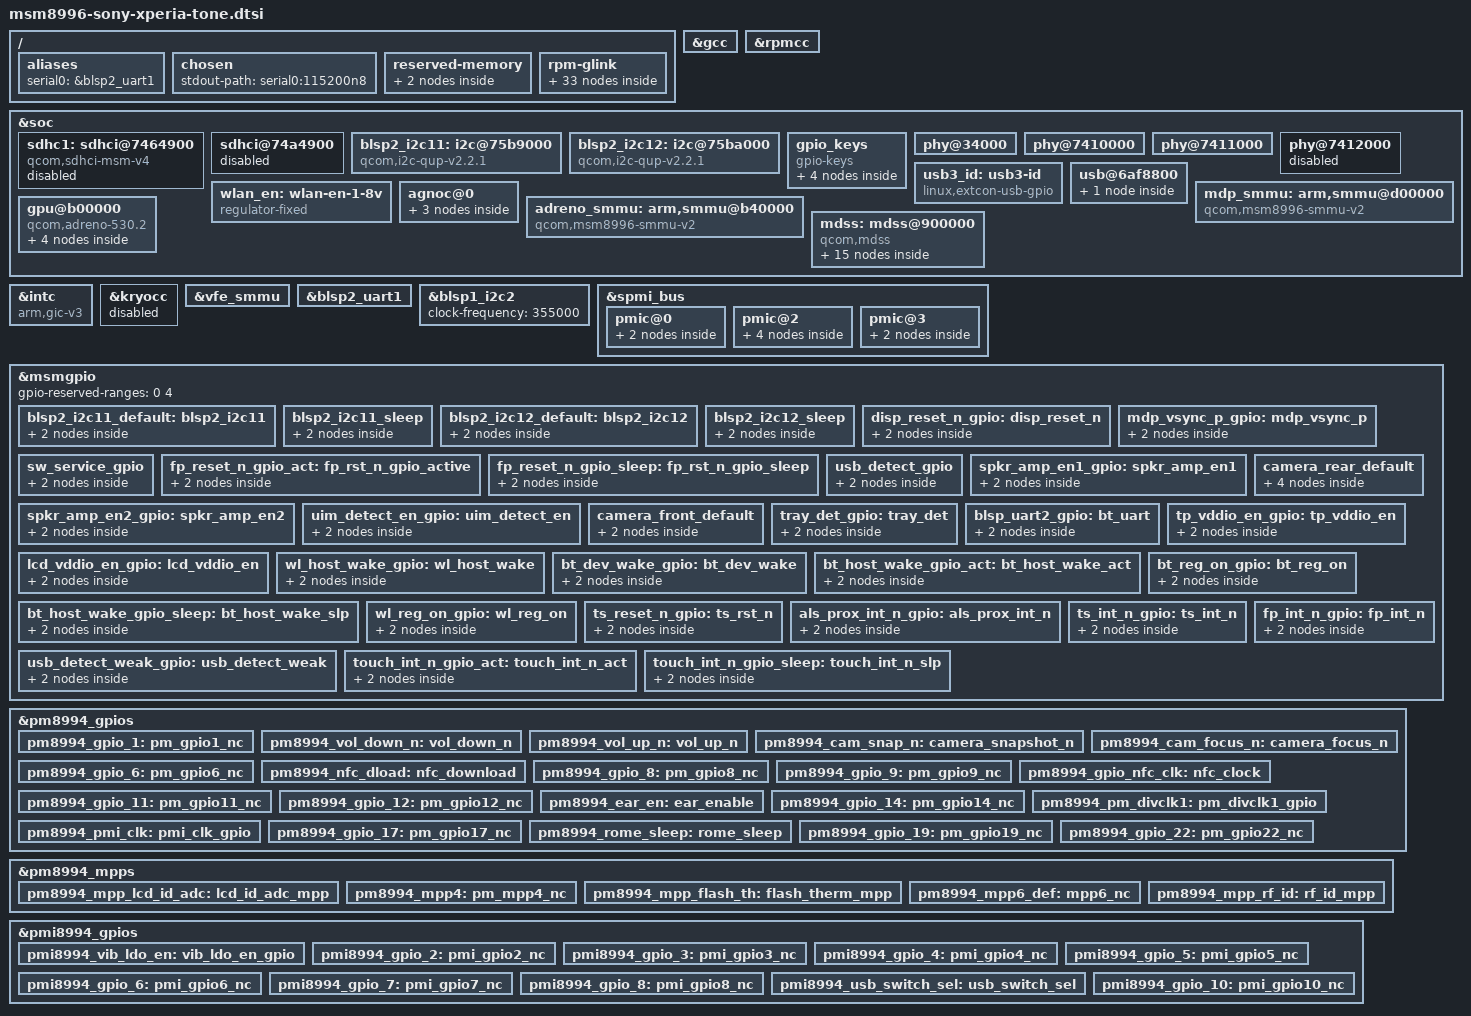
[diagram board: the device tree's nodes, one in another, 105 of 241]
// SPDX-License-Identifier: GPL-2.0
/* Copyright (C) 2016 Sony Mobile Communications Inc.
 * Copyright (c) 2019 AngeloGioacchino Del Regno <kholk11@gmail.com>
 */

#include "msm8996.dtsi"
#include "pm8994.dtsi"
#include "pmi8994.dtsi"
#include <dt-bindings/input/input.h>
#include <dt-bindings/input/gpio-keys.h>
#include <dt-bindings/gpio/gpio.h>
#include <dt-bindings/pinctrl/qcom,pmic-gpio.h>
#include <dt-bindings/pinctrl/qcom,pmic-mpp.h>

/ {
	aliases {
		serial0 = &blsp2_uart1;
	};

	chosen {
		stdout-path = "serial0:115200n8";
	};

	reserved-memory {
		ramoops {
			compatible = "removed-dma-pool", "ramoops";
			no-map;
			reg = <0 0x57f00000 0 0x00100000>;
			record-size = <0x20000>;
			console-size = <0x40000>;
			ftrace-size = <0x20000>;
			pmsg-size = <0x20000>;
			ecc-size = <16>;
			status = "ok";
		};

		zap_shader_region: gpu@8f200000 {
			compatible = "shared-dma-pool";
			reg = <0x0 0x91700000 0x0 0xa00000>;
			no-map;
			status = "ok";
		};
	};

	rpm-glink {
		rpm_requests {
			pm8994-regulators {
				vdd_l1-supply = <&pm8994_s3>;
				vdd_l2_l26_l28-supply = <&pm8994_s3>;
				vdd_l3_l11-supply = <&pm8994_s3>;
				vdd_l4_l27_l31-supply = <&pm8994_s3>;
				vdd_l5_l7-supply = <&pm8994_s5>;
				vdd_l14_l15-supply = <&pm8994_s5>;
				vdd_l20_l21-supply = <&pm8994_s5>;
				vdd_l25-supply = <&pm8994_s3>;

				s3 {
					regulator-min-microvolt = <1300000>;
					regulator-max-microvolt = <1300000>;
				};

				s4 {
					regulator-min-microvolt = <1800000>;
					regulator-max-microvolt = <1800000>;
					regulator-always-on;
				};
				s5 {
					regulator-min-microvolt = <2150000>;
					regulator-max-microvolt = <2150000>;
				};
				s7 {
					regulator-min-microvolt = <800000>;
					regulator-max-microvolt = <800000>;
				};

				l1 {
					regulator-min-microvolt = <1000000>;
					regulator-max-microvolt = <1000000>;
				};
				l2 {
					regulator-min-microvolt = <1250000>;
					regulator-max-microvolt = <1250000>;
				};
				l3 {
					regulator-min-microvolt = <1100000>;
					regulator-max-microvolt = <1100000>;
				};
				l4 {
					regulator-min-microvolt = <1225000>;
					regulator-max-microvolt = <1225000>;
				};
				l6 {};
				l7 {};
				l8 {
					regulator-min-microvolt = <1800000>;
					regulator-max-microvolt = <1800000>;
				};
				l9 {
					regulator-min-microvolt = <1800000>;
					regulator-max-microvolt = <1800000>;
				};
				l10 {
					regulator-min-microvolt = <1800000>;
					regulator-max-microvolt = <1800000>;
				};
				l11 {};
				l12 {
					regulator-min-microvolt = <1800000>;
					regulator-max-microvolt = <1800000>;
				};
				l13 {
					regulator-min-microvolt = <1800000>;
					regulator-max-microvolt = <2950000>;
				};
				l14 {};
				l15 {
					regulator-min-microvolt = <1800000>;
					regulator-max-microvolt = <1800000>;
				};
				l16 {
					regulator-min-microvolt = <2700000>;
					regulator-max-microvolt = <2700000>;
				};
				l17 {
					regulator-min-microvolt = <2200000>;
					regulator-max-microvolt = <2500000>;
				};
				l18 {
					regulator-min-microvolt = <1800000>;
					regulator-max-microvolt = <1800000>;
				};
				l20 {
					regulator-min-microvolt = <2950000>;
					regulator-max-microvolt = <2950000>;
					regulator-allow-set-load;
				};
				l21 {
					regulator-min-microvolt = <2950000>;
					regulator-max-microvolt = <2950000>;
				};
				l22 {
					regulator-min-microvolt = <3000000>;
					regulator-max-microvolt = <3000000>;
				};
				l23 {
					regulator-min-microvolt = <2700000>;
					regulator-max-microvolt = <2700000>;
				};
				l24 {
					regulator-min-microvolt = <3075000>;
					regulator-max-microvolt = <3075000>;
					regulator-allow-set-load;
				};
				l25 {
					regulator-min-microvolt = <1200000>;
					regulator-max-microvolt = <1200000>;
					regulator-allow-set-load;
				};
				l27 {
					regulator-min-microvolt = <1000000>;
					regulator-max-microvolt = <1200000>;
				};
				l28 { /* This should be 1.0V for USB, 0.925 for DSI :\ */
					regulator-min-microvolt = <925000>;
					regulator-max-microvolt = <925000>;
					regulator-allow-set-load;
				};
				l29 {
					regulator-min-microvolt = <2700000>;
					regulator-max-microvolt = <2700000>;
				};
				l32 {
					regulator-min-microvolt = <1800000>;
					regulator-max-microvolt = <1800000>;
				};
			};
		};
	};
};

&gcc {
	status = "ok";
};

&rpmcc {
	status = "ok";
};

&soc {
	sdhc1: sdhci@7464900 {
		compatible = "qcom,sdhci-msm-v4";
		reg = <0x7464900 0x500>, <0x7464000 0x800>;
		reg-names = "hc_mem", "core_mem";

		interrupts = <GIC_SPI 141 IRQ_TYPE_LEVEL_HIGH>,
			     <GIC_SPI 134 IRQ_TYPE_LEVEL_HIGH>;
		interrupt-names = "hc_irq", "pwr_irq";

		clock-names = "iface", "core", "xo";
		clocks = <&gcc GCC_SDCC1_AHB_CLK>,
			 <&gcc GCC_SDCC1_APPS_CLK>,
			 <&xo_board>;

		mmc-hs400-1_8v;
		bus-width = <8>;
		non-removable;
		status = "disabled";
	};

	sdhci@74a4900 {
		pinctrl-names = "default", "sleep";
		pinctrl-0 = <&sdc2_clk_on &sdc2_cmd_on &sdc2_data_on
				&tray_det_gpio>;
		pinctrl-1 = <&sdc2_clk_off &sdc2_cmd_off &sdc2_data_off
				&tray_det_gpio>;
		cd-gpios = <&msmgpio 40 GPIO_ACTIVE_LOW>;
		vmmc-supply = <&pm8994_l21>;
		vqmmc-supply = <&pm8994_l13>;
		status = "disabled";
	};

	blsp2_i2c11: i2c@75b9000 {
		compatible = "qcom,i2c-qup-v2.2.1";
		reg = <0x75b9000 0x1000>;
		interrupts = <GIC_SPI 102 IRQ_TYPE_LEVEL_HIGH>;
		clocks = <&gcc GCC_BLSP2_AHB_CLK>,
			<&gcc GCC_BLSP2_QUP5_I2C_APPS_CLK>;
		clock-names = "iface", "core";
		pinctrl-names = "default", "sleep";
		pinctrl-0 = <&blsp2_i2c11_default>;
		pinctrl-1 = <&blsp2_i2c11_sleep>;
		#address-cells = <1>;
		#size-cells = <0>;

		clock-frequency = <355000>;
		status = "ok";
	};

	blsp2_i2c12: i2c@75ba000 {
		compatible = "qcom,i2c-qup-v2.2.1";
		reg = <0x75ba000 0x1000>;
		interrupts = <GIC_SPI 102 IRQ_TYPE_LEVEL_HIGH>;
		clocks = <&gcc GCC_BLSP2_AHB_CLK>,
			<&gcc GCC_BLSP2_QUP6_I2C_APPS_CLK>;
		clock-names = "iface", "core";
		pinctrl-names = "default", "sleep";
		pinctrl-0 = <&blsp2_i2c12_default>;
		pinctrl-1 = <&blsp2_i2c12_sleep>;
		#address-cells = <1>;
		#size-cells = <0>;

		clock-frequency = <355000>;
		status = "ok";
	};

	gpio_keys {
		compatible = "gpio-keys";
		input-name = "gpio-keys";
		#address-cells = <1>;
		#size-cells = <0>;
		autorepeat;

		button@0 {
			label = "Volume Down";
			gpios = <&pm8994_gpios 2 GPIO_ACTIVE_LOW>;
			linux,input-type = <1>;
			linux,code = <KEY_VOLUMEDOWN>;
			wakeup-source;
			debounce-interval = <15>;
		};

		button@1 {
			label = "Volume Up";
			gpios = <&pm8994_gpios 3 GPIO_ACTIVE_LOW>;
			linux,input-type = <1>;
			linux,code = <KEY_VOLUMEUP>;
			wakeup-source;
			debounce-interval = <15>;
		};

		button@2 {
			label = "Camera Snapshot";
			gpios = <&pm8994_gpios 4 GPIO_ACTIVE_LOW>;
			linux,input-type = <1>;
			linux,code = <KEY_CAMERA>;
			wakeup-source;
			wakeup-event-action = <EV_ACT_ASSERTED>;
			debounce-interval = <15>;
		};

		button@3 {
			label = "Camera Focus";
			gpios = <&pm8994_gpios 5 GPIO_ACTIVE_LOW>;
			linux,input-type = <1>;
			linux,code = <KEY_CAMERA_FOCUS>;
			wakeup-source;
			debounce-interval = <15>;
		};
	};

	phy@34000 {
		status = "okay";
	};

	phy@7410000 {
		status = "okay";
	};

	phy@7411000 {
		status = "okay";
	};

	phy@7412000 {
		status = "disabled";
	};

	usb3_id: usb3-id {
		compatible = "linux,extcon-usb-gpio";
		id-gpio = <&msmgpio 24 GPIO_ACTIVE_LOW>;
		pinctrl-names = "default";
		pinctrl-0 = <&usb_detect_gpio>;
	};

	usb@6af8800 {
		status = "okay";
		extcon = <&usb3_id>;

		clock-names = "cfg_noc", "core", "iface", "mock_utmi",
				"sleep", "ahb2phy";
		resets = <&gcc GCC_USB_30_BCR>,
			 <&gcc GCC_USB_PHY_CFG_AHB2PHY_BCR>;
		reset-names = "core_reset", "ahb2phy_reset";

		interrupts = <GIC_SPI 347 IRQ_TYPE_LEVEL_HIGH>,
			     <GIC_SPI 243 IRQ_TYPE_LEVEL_HIGH>;
		interrupt-names = "hs_phy_irq", "ss_phy_irq";

		dwc3@6a00000 {
			extcon = <&usb3_id>;
			dr_mode = "otg";
			maximum-speed = "high-speed";
			snps,has-lpm-erratum;
			snps,is-utmi-l1-suspend;
			snps,hird-threshold = /bits/ 8 <0x0>;
			phys = <&hsusb_phy1>; //, <&ssusb_phy_0>;
			phy-names = "usb2-phy"; //, "usb3-phy";
		};
	};

	wlan_en: wlan-en-1-8v {
		pinctrl-names = "default";
		pinctrl-0 = <&wl_reg_on_gpio>;
		compatible = "regulator-fixed";
		regulator-name = "wlan-en-regulator";
		regulator-min-microvolt = <1800000>;
		regulator-max-microvolt = <1800000>;

		gpio = <&msmgpio 84 GPIO_ACTIVE_HIGH>;

		/* WLAN card specific delay */
		startup-delay-us = <70000>;
		enable-active-high;
	};

	agnoc@0 {
		pcie@600000 {
			status = "okay";
			perst-gpio = <&msmgpio 35 GPIO_ACTIVE_LOW>;
			wake-gpio = <&msmgpio 37 GPIO_ACTIVE_LOW>;
			vddpe-3v3-supply = <&wlan_en>;
		};

		pcie@608000 {
			status = "disabled";
			perst-gpio = <&msmgpio 130 GPIO_ACTIVE_LOW>;
		};

		pcie@610000 {
			status = "disabled";
			perst-gpio = <&msmgpio 114 GPIO_ACTIVE_LOW>;
			wake-gpio = <&msmgpio 116 GPIO_ACTIVE_LOW>;
		};
	};

	adreno_smmu: arm,smmu@b40000 {
		compatible = "qcom,msm8996-smmu-v2", "qcom,smmu-v2";
		reg = <0xb40000 0x10000>;

		#global-interrupts = <1>;
		interrupts = <GIC_SPI 334 IRQ_TYPE_LEVEL_HIGH>,
			     <GIC_SPI 329 IRQ_TYPE_LEVEL_HIGH>,
			     <GIC_SPI 330 IRQ_TYPE_LEVEL_HIGH>;
		#iommu-cells = <1>;

/*
		clocks = <&mmcc GPU_AHB_CLK>,
			<&gcc GCC_MMSS_BIMC_GFX_CLK>;
		clock-names = "bus", "iface";
*/
		clocks = <&mmcc MMSS_MMAGIC_AHB_CLK>,
			<&mmcc MMSS_MMAGIC_CFG_AHB_CLK>,
			<&mmcc GPU_AHB_CLK>,
			<&gcc GCC_MMSS_BIMC_GFX_CLK>,
			<&gcc GCC_BIMC_GFX_CLK>;
		clock-names = "mmagic_ahb_clk", "mmagic_cfg_ahb_clk", "gpu_ahb_clk",
			"gcc_mmss_bimc_gfx_clk", "gcc_bimc_gfx_clk";

		power-domains = <&mmcc GPU_GDSC>;

		status = "ok";
	};

	mdp_smmu: arm,smmu@d00000 {
		compatible = "qcom,msm8996-smmu-v2", "qcom,smmu-v2";
		reg = <0xd00000 0x10000>;

		#global-interrupts = <1>;
		interrupts = <GIC_SPI 73 IRQ_TYPE_LEVEL_HIGH>,
			     <GIC_SPI 320 IRQ_TYPE_LEVEL_HIGH>,
			     <GIC_SPI 321 IRQ_TYPE_LEVEL_HIGH>;
		#iommu-cells = <1>;

		power-domains = <&mmcc MDSS_GDSC>;
/*
		clocks = <&mmcc SMMU_MDP_AHB_CLK>,
			 <&mmcc SMMU_MDP_AXI_CLK>;
		clock-names = "iface", "bus";
*/
		clocks = <&mmcc MMSS_MMAGIC_AHB_CLK>,
			<&mmcc MMSS_MMAGIC_CFG_AHB_CLK>,
			<&mmcc SMMU_MDP_AHB_CLK>,
			<&mmcc SMMU_MDP_AXI_CLK>,
			<&mmcc MMAGIC_MDSS_AXI_CLK>;
		clock-names = "mmagic_ahb_clk", "mmagic_cfg_ahb_clk",
			"mdp_ahb_clk", "mdp_axi_clk",
			"mmagic_mdss_axi_clk";

		status = "ok";
	};

	gpu@b00000 {
		compatible = "qcom,adreno-530.2", "qcom,adreno";
		#stream-id-cells = <16>;

		reg = <0xb00000 0x3f000>;
		reg-names = "kgsl_3d0_reg_memory";

		interrupts = <GIC_SPI 300 IRQ_TYPE_LEVEL_HIGH>;
		interrupt-names = "kgsl_3d0_irq";

		clocks = <&mmcc GPU_GX_GFX3D_CLK>,
			<&mmcc GPU_AHB_CLK>,
			<&mmcc GPU_GX_RBBMTIMER_CLK>,
			<&gcc GCC_BIMC_GFX_CLK>,
			<&gcc GCC_MMSS_BIMC_GFX_CLK>;

		clock-names = "core",
			"iface",
			"rbbmtimer",
			"mem",
			"mem_iface";

		power-domains = <&mmcc GPU_GDSC>;
		vdd-supply = <&pmi8994_s2>;
		iommus = <&adreno_smmu 0>;

		qcom,gpu-quirk-two-pass-use-wfi;
		qcom,gpu-quirk-fault-detect-mask;

		/* This is a safe speed for bring up in all bin levels.
		 * This isn't the fastest the chip can go, but we can
		 * get there eventually */
		qcom,gpu-pwrlevels {
			compatible = "qcom,gpu-pwrlevels";
			qcom,gpu-pwrlevel@0 {
				qcom,gpu-freq = <510000000>;
			};
			qcom,gpu-pwrlevel@1 {
				qcom,gpu-freq = <27000000>;
			};
		};

		zap-shader {
			memory-region = <&zap_shader_region>;
		};
	};

	mdss: mdss@900000 {
		compatible = "qcom,mdss";

		reg = <0x900000 0x1000>,
		      <0x9b0000 0x1040>,
		      <0x9b8000 0x1040>;
		reg-names = "mdss_phys",
			    "vbif_phys",
			    "vbif_nrt_phys";

		power-domains = <&mmcc MDSS_GDSC>;
		interrupts = <GIC_SPI 83 IRQ_TYPE_LEVEL_HIGH>;

		interrupt-controller;
		#interrupt-cells = <1>;

		clocks = <&mmcc MDSS_AHB_CLK>,
			 <&mmcc MDSS_AXI_CLK>,
			 <&mmcc MDSS_VSYNC_CLK>;
		clock-names = "iface", "bus", "vsync";

		#address-cells = <1>;
		#size-cells = <1>;
		ranges;

		mdp: mdp@901000 {
			compatible = "qcom,mdp5";
			reg = <0x901000 0x90000>;
			reg-names = "mdp_phys";

			interrupt-parent = <&mdss>;
			interrupts = <0 IRQ_TYPE_LEVEL_HIGH>;

			clocks = <&mmcc MDSS_AHB_CLK>,
				 <&mmcc MDSS_AXI_CLK>,
				 <&mmcc MDSS_MDP_CLK>,
				 <&mmcc SMMU_MDP_AXI_CLK>,
				 <&mmcc MDSS_VSYNC_CLK>;
			clock-names = "iface",
				      "bus",
				      "core",
				      "iommu",
				      "vsync";

			iommus = <&mdp_smmu 0>;

			ports {
				#address-cells = <1>;
				#size-cells = <0>;

				port@0 {
					reg = <0>;
					mdp5_intf1_out: endpoint {
						remote-endpoint = <&dsi0_in>;
					};
				};
			};
		};

		dsi0: dsi@994000 {
			compatible = "qcom,mdss-dsi-ctrl";
			reg = <0x994000 0x400>;
			reg-names = "dsi_ctrl";
			qcom,dsi-host-index = <0>;

			interrupt-parent = <&mdss>;
			interrupts = <4 0>;

			#address-cells = <1>;
			#size-cells = <0>;

			clocks = <&mmcc MDSS_MDP_CLK>,
				 <&mmcc MDSS_AHB_CLK>,
				 <&mmcc MDSS_AXI_CLK>,
				 <&mmcc MMSS_MISC_AHB_CLK>,
				 <&mmcc MDSS_BYTE0_CLK>,
				 <&mmcc MDSS_PCLK0_CLK>,
				 <&mmcc MDSS_ESC0_CLK>;
			clock-names = "mdp_core",
				      "iface",
				      "bus",
				      "core_mmss",
				      "byte",
				      "pixel",
				      "core";

			assigned-clocks =
					<&mmcc BYTE0_CLK_SRC>,
					<&mmcc PCLK0_CLK_SRC>;
			assigned-clock-parents =
					<&dsi_phy0 0>,
					<&dsi_phy0 1>;

			vdda-supply = <&pm8994_l2>;
			vcca-supply = <&pm8994_l28>;

			phys = <&dsi_phy0>;
			phy-names = "dsi-phy";

			ports {
				#address-cells = <1>;
				#size-cells = <0>;

				port@0 {
					reg = <0>;
					dsi0_in: endpoint {
						remote-endpoint = <&mdp5_intf1_out>;
					};
				};

				port@1 {
					reg = <1>;
					dsi0_out: endpoint {
						remote-endpoint = <&panel_in>;
						data-lanes = <0 1 2 3>;
					};
				};
			};

			lgd_panel0: lgd-panel@0 {
				compatible = "lgd,syn-incell-fhd-ips-lcd";
				reg = <0>;
				status = "okay";
				disp-te-gpio = <&msmgpio 10 0>;

				vddio-supply = <&pm8994_s4>;
				avdd-supply = <&pm8994_l22>;

				pvddio-gpio = <&msmgpio 51 GPIO_ACTIVE_HIGH>;
				preset-gpio = <&msmgpio 8 GPIO_ACTIVE_HIGH>;
				tvddio-gpio = <&msmgpio 50 GPIO_ACTIVE_HIGH>;
				treset-gpio = <&msmgpio 89 GPIO_ACTIVE_HIGH>;

				pinctrl-names = "default";
				pinctrl-0 =
					<&mdp_vsync_p_gpio &disp_reset_n_gpio
					&tp_vddio_en_gpio &lcd_vddio_en_gpio
					&ts_reset_n_gpio>;

				ports {
					#address-cells = <1>;
					#size-cells = <0>;
					port@0 {
						reg = <0>;
						panel_in: endpoint {
							remote-endpoint = <&dsi0_out>;
						};
					};
				};
			};
		};

		dsi_phy0: dsi-phy@994800 {
			compatible = "qcom,dsi-phy-14nm";
			reg = <0x994800 0x188>,
			      <0x994400 0x100>,
			      <0x994500 0x300>;
			reg-names = "dsi_pll",
				    "dsi_phy",
				    "dsi_phy_lane";

			#clock-cells = <1>;
			#phy-cells = <0>;

			power-domains = <&mmcc MDSS_GDSC>;
			vcca-supply = <&pm8994_l28>;

			clocks = <&mmcc MDSS_AHB_CLK>;
			clock-names = "iface";
		};
	};

};

&intc {
	compatible = "arm,gic-v3", "qcom,msm8996-gic-v3";
};

&kryocc {
	status = "disabled";
};

&vfe_smmu {
	status = "ok";
};

&blsp2_uart1 {
	status = "ok";
	pinctrl-names = "default", "sleep";
	pinctrl-0 = <&blsp2_uart1_2pins_default>;
	pinctrl-1 = <&blsp2_uart1_2pins_sleep>;
};

&blsp1_i2c2 {
	clock-frequency = <355000>;
	status = "ok";
};

&spmi_bus {
	pmic@0 {
		pon@800 {
			resin {
				compatible = "qcom,pm8941-resin";
				interrupts = <0x0 0x8 1 IRQ_TYPE_EDGE_BOTH>;
				debounce = <15625>;
				bias-pull-up;
				linux,code = <KEY_VOLUMEUP>;
			};
		};
	};

	pmic@2 {
		pmi8994_mpps: pmi-mpps {
			compatible = "qcom,pmi8994-mpp"; /* TODO: Not supported! */
			reg = <0xa000 0x400>;

			interrupts = <0x2 0xa0 0 IRQ_TYPE_NONE>,
				<0x2 0xa1 0 IRQ_TYPE_NONE>,
				<0x2 0xa2 0 IRQ_TYPE_NONE>,
				<0x2 0xa3 0 IRQ_TYPE_NONE>;
			interrupt-names = "pmi8994_mpp1", "pmi8994_mpp2",
					  "pmi8994_mpp3", "pmi8994_mpp4";

			gpio-controller;
			#gpio-cells = <2>;
		};
	};

	pmic@3 {
		regulators {
			compatible = "qcom,pmi8994-regulators";
			#address-cells = <1>;
			#size-cells = <1>;

			/* GPU GX GDSC Supply */
			pmi8994_s2: s2@1700 {
				reg = <0x1700 0x100>;
				status = "ok";
				regulator-min-microvolt = <400000>;
				regulator-max-microvolt = <1015000>;
				regulator-always-on;
			};
		};
	};
};

/* Pins */
&msmgpio {
	gpio-reserved-ranges = <0 4>;

	blsp2_i2c11_default: blsp2_i2c11 {
		pinmux {
			function = "blsp_i2c11";
			pins = "gpio60", "gpio61";
		};
		pinconf {
			pins = "gpio60", "gpio61";
			drive-strength = <16>;
			bias-disable;
		};
	};

	blsp2_i2c11_sleep: blsp2_i2c11_sleep {
		pinmux {
			function = "gpio";
			pins = "gpio60", "gpio61";
		};
		pinconf {
			pins = "gpio60", "gpio61";
			drive-strength = <2>;
			bias-disable;
		};
	};

	blsp2_i2c12_default: blsp2_i2c12 {
		pinmux {
			function = "blsp_i2c12";
			pins = "gpio87", "gpio88";
		};
		pinconf {
			pins = "gpio87", "gpio88";
			drive-strength = <16>;
			bias-disable;
		};
	};

	blsp2_i2c12_sleep: blsp2_i2c12_sleep {
		pinmux {
			function = "gpio";
			pins = "gpio87", "gpio88";
		};
		pinconf {
			pins = "gpio87", "gpio88";
			drive-strength = <2>;
			bias-disable;
		};
	};

	disp_reset_n_gpio: disp_reset_n {
		pinmux {
			pins = "gpio8";
			function = "gpio";
		};

		pinconf {
			pins = "gpio8";
			drive-strength = <2>;
			bias-disable;
		};
	};

	mdp_vsync_p_gpio: mdp_vsync_p {
		pinmux {
			pins = "gpio10";
			function = "mdp_vsync";
		};

		pinconf {
			pins = "gpio10";
			drive-strength = <2>;
			bias-disable;
		};
	};

	sw_service_gpio: sw_service_gpio {
		pinmux {
			pins = "gpio16";
			function = "gpio";
		};

		pinconf {
			pins = "gpio16";
			drive-strength = <2>;
			bias-pull-up;
		};
	};

	fp_reset_n_gpio_act: fp_rst_n_gpio_active {
		pinmux {
			pins = "gpio21";
			function = "gpio";
		};

		pinconf {
			pins = "gpio21";
			drive-strength = <2>;
			bias-disable;
			output-high;
		};
	};

	fp_reset_n_gpio_sleep: fp_rst_n_gpio_sleep {
		pinmux {
			pins = "gpio21";
			function = "gpio";
		};

		pinconf {
			pins = "gpio21";
			drive-strength = <2>;
			bias-disable;
			output-low;
		};
	};

	usb_detect_gpio: usb_detect_gpio {
		pinmux {
			pins = "gpio24";
			function = "gpio";
		};

		pinconf {
			pins = "gpio24";
			drive-strength = <2>;
			bias-disable;
			output-low;
		};
	};

	spkr_amp_en1_gpio: spkr_amp_en1 {
		pinmux {
			pins = "gpio27";
			function = "gpio";
		};

		pinconf {
			pins = "gpio27";
			drive-strength = <2>;
			bias-disable;
			output-low;
		};
	};

	spkr_amp_en2_gpio: spkr_amp_en2 {
		pinmux {
			pins = "gpio28";
			function = "gpio";
		};

		pinconf {
			pins = "gpio28";
			drive-strength = <2>;
			bias-disable;
			output-low;
		};
	};

	uim_detect_en_gpio: uim_detect_en {
		pinmux {
			pins = "gpio29";
			function = "gpio";
		};

		pinconf {
			pins = "gpio29";
			drive-strength = <2>;
			bias-disable;
			output-low;
		};
	};


	camera_rear_default {
		config_pwdn {
			drive-strength = <2>;
			output-low;
		};

		mux_rst {
			pins = "gpio30";
		};

		config_rst {
			pins = "gpio30";
			drive-strength = <2>;
			output-low;
		};

		config_mclk0 {
			drive-strength = <2>;
			output-low;
		};
	};

	camera_front_default {
		config_rst {
			drive-strength = <2>;
			output-low;
		};

		config_mclk2 {
			drive-strength = <2>;
			output-low;
		};
	};

	tray_det_gpio: tray_det {
		pinmux {
			pins = "gpio40";
			function = "gpio";
		};

		pinconf {
			pins = "gpio40";
			drive-strength = <2>;
			bias-disable;
		};
	};

	blsp_uart2_gpio: bt_uart {
		pinmux {
			function = "blsp_uart2";
			pins = "gpio41", "gpio42", "gpio43", "gpio44";
		};
		pinconf {
			pins = "gpio41", "gpio42", "gpio43", "gpio44";
			drive-strength = <2>;
			bias-disable;
		};
	};

	tp_vddio_en_gpio: tp_vddio_en {
		pinmux {
			pins = "gpio50";
			function = "gpio";
		};

		pinconf {
			pins = "gpio50";
			drive-strength = <2>;
			bias-disable;
			output-low;
		};
	};

	lcd_vddio_en_gpio: lcd_vddio_en {
		pinmux {
			pins = "gpio51";
			function = "gpio";
		};

		pinconf {
			pins = "gpio51";
			drive-strength = <2>;
			bias-disable;
			output-low;
		};
	};

	wl_host_wake_gpio: wl_host_wake {
		pinmux {
			pins = "gpio79";
			function = "gpio";
		};

		pinconf {
			pins = "gpio79";
			drive-strength = <2>;
			bias-pull-down;
		};
	};

	bt_dev_wake_gpio: bt_dev_wake {
		pinmux {
			pins = "gpio81";
			function = "gpio";
		};

		pinconf {
			pins = "gpio81";
			drive-strength = <2>;
			bias-disable;
			output-low;
		};
	};

	bt_host_wake_gpio_act: bt_host_wake_act {
		pinmux {
			pins = "gpio82";
			function = "gpio";
		};

		pinconf {
			pins = "gpio82";
			drive-strength = <2>;
			bias-disable;
		};
	};

	bt_host_wake_gpio_sleep: bt_host_wake_slp {
		pinmux {
			pins = "gpio82";
			function = "gpio";
		};

		pinconf {
			pins = "gpio82";
			drive-strength = <2>;
			bias-pull-down;
		};
	};

	bt_reg_on_gpio: bt_reg_on {
		pinmux {
			pins = "gpio83";
			function = "gpio";
		};

		pinconf {
			pins = "gpio83";
			drive-strength = <2>;
			bias-disable;
			output-low;
		};
	};

	wl_reg_on_gpio: wl_reg_on {
		pinmux {
			pins = "gpio84";
			function = "gpio";
		};

		pinconf {
			pins = "gpio84";
			drive-strength = <2>;
			bias-disable;
			output-low;
		};
	};

	ts_reset_n_gpio: ts_rst_n {
		pinmux {
			pins = "gpio89";
			function = "gpio";
		};

		pinconf {
			pins = "gpio89";
			drive-strength = <2>;
		};
	};

	als_prox_int_n_gpio: als_prox_int_n {
		pinmux {
			pins = "gpio120";
			function = "gpio";
		};

		pinconf {
			pins = "gpio120";
			drive-strength = <2>;
			bias-disable;
		};
	};

	ts_int_n_gpio: ts_int_n {
		pinmux {
			pins = "gpio125";
			function = "gpio";
		};

		pinconf {
			pins = "gpio125";
			drive-strength = <2>;
		};
	};

	usb_detect_weak_gpio: usb_detect_weak {
		pinmux {
			pins = "gpio130";
			function = "gpio";
		};

		pinconf {
			pins = "gpio130";
			drive-strength = <2>;
			bias-disable;
			output-low;
		};
	};

	fp_int_n_gpio: fp_int_n {
		pinmux {
			pins = "gpio132";
			function = "gpio";
		};

		pinconf {
			pins = "gpio132";
			drive-strength = <2>;
			bias-pull-down;
		};
	};

	touch_int_n_gpio_act: touch_int_n_act {
		pinmux {
			pins = "gpio125";
			function = "touch_int_n";
		};
		pinconf {
			pins = "gpio125";
			drive-strength = <2>;
			bias-pull-up;
		};
	};

	touch_int_n_gpio_sleep: touch_int_n_slp {
		pinmux {
			pins = "gpio125";
			function = "touch_int_n";
		};
		pinconf {
			pins = "gpio125";
			drive-strength = <2>;
			bias-pull-down;
		};
	};
};

/* PMIC Pins */
&pm8994_gpios {
	pinctrl-names = "default";
	pinctrl-0 = <&pm8994_gpio_1 &pm8994_vol_down_n &pm8994_vol_up_n
		     &pm8994_cam_snap_n &pm8994_cam_focus_n &pm8994_gpio_6
		     &pm8994_nfc_dload &pm8994_gpio_8 &pm8994_gpio_9
		     &pm8994_gpio_nfc_clk &pm8994_gpio_11 &pm8994_gpio_12
		     &pm8994_ear_en &pm8994_gpio_14 &pm8994_pm_divclk1
		     &pm8994_pmi_clk &pm8994_gpio_17 &pm8994_rome_sleep
		     &pm8994_gpio_19 &pm8994_gpio_22>;

	gpio-line-names =
		"NC",
		"VOL_DOWN_N",
		"VOL_UP_N",
		"SNAPSHOT_N",
		"FOCUS_N",
		"NC",
		"NFC_VEN",
		"NC",
		"NC",
		"NC",
		"NC",
		"NC",
		"EAR_EN",
		"NC",
		"PM_DIVCLK1",
		"PMI_CLK",
		"NC",
		"WL_SLEEP_CLK",
		"NC",
		"PMIC_SPON",
		"UIM_BATT_ALARM",
		"PMK_SLEEP_CLK";

	pm8994_gpio_1: pm_gpio1_nc {
		pins = "gpio1";
		function = PMIC_GPIO_FUNC_NORMAL;
		drive-push-pull;
		bias-high-impedance;
	};

	pm8994_vol_down_n: vol_down_n {
		pins = "gpio2";
		function = PMIC_GPIO_FUNC_NORMAL;
		drive-push-pull;
		input-enable;
		bias-pull-up;
		qcom,drive-strength = <PMIC_GPIO_STRENGTH_NO>;
		power-source = <PM8994_GPIO_S4>;
	};

	pm8994_vol_up_n: vol_up_n {
		pins = "gpio3";
		function = PMIC_GPIO_FUNC_NORMAL;
		drive-push-pull;
		input-enable;
		bias-pull-up;
		power-source = <PM8994_GPIO_S4>;
	};

	pm8994_cam_snap_n: camera_snapshot_n {
		pins = "gpio4";
		function = PMIC_GPIO_FUNC_NORMAL;
		drive-push-pull;
		input-enable;
		bias-pull-up;
		qcom,drive-strength = <PMIC_GPIO_STRENGTH_NO>;
		power-source = <PM8994_GPIO_S4>;
	};

	pm8994_cam_focus_n: camera_focus_n {
		pins = "gpio5";
		function = PMIC_GPIO_FUNC_NORMAL;
		drive-push-pull;
		input-enable;
		bias-pull-up;
		qcom,drive-strength = <PMIC_GPIO_STRENGTH_NO>;
		power-source = <PM8994_GPIO_S4>;
	};

	pm8994_gpio_6: pm_gpio6_nc {
		pins = "gpio6";
		function = PMIC_GPIO_FUNC_NORMAL;
		drive-push-pull;
		bias-high-impedance;
		power-source = <PM8994_GPIO_VPH>;
	};

	pm8994_nfc_dload: nfc_download {
		pins = "gpio7";
		function = PMIC_GPIO_FUNC_NORMAL;
		output-low;
		drive-push-pull;
		bias-disable;
		qcom,drive-strength = <PMIC_GPIO_STRENGTH_LOW>;
		power-source = <PM8994_GPIO_S4>;
	};

	pm8994_gpio_8: pm_gpio8_nc {
		pins = "gpio8";
		function = PMIC_GPIO_FUNC_NORMAL;
		output-low;
		drive-push-pull;
		bias-high-impedance;
		qcom,drive-strength = <PMIC_GPIO_STRENGTH_NO>;
		power-source = <PM8994_GPIO_VPH>;
	};

	pm8994_gpio_9: pm_gpio9_nc {
		pins = "gpio9";
		function = PMIC_GPIO_FUNC_NORMAL;
		output-high;
		drive-push-pull;
		bias-high-impedance;
		qcom,drive-strength = <PMIC_GPIO_STRENGTH_LOW>;
		power-source = <PM8994_GPIO_VPH>;
	};

	pm8994_gpio_nfc_clk: nfc_clock {
		pins = "gpio10";
		function = PMIC_GPIO_FUNC_NORMAL;
		input-enable;
		drive-push-pull;
		bias-pull-down;
		qcom,drive-strength = <PMIC_GPIO_STRENGTH_NO>;
		power-source = <PM8994_GPIO_S4>;
	};

	pm8994_gpio_11: pm_gpio11_nc {
		pins = "gpio11";
		function = PMIC_GPIO_FUNC_NORMAL;
		drive-push-pull;
		bias-high-impedance;
		power-source = <PM8994_GPIO_VPH>;
	};

	pm8994_gpio_12: pm_gpio12_nc {
		pins = "gpio12";
		function = PMIC_GPIO_FUNC_NORMAL;
		drive-push-pull;
		bias-high-impedance;
		power-source = <PM8994_GPIO_VPH>;
	};

	pm8994_ear_en: ear_enable {
		pins = "gpio13";
		function = PMIC_GPIO_FUNC_NORMAL;
		output-high;
		drive-push-pull;
		bias-disable;
		qcom,drive-strength = <PMIC_GPIO_STRENGTH_LOW>;
		power-source = <PM8994_GPIO_S4>;
	};

	pm8994_gpio_14: pm_gpio14_nc {
		pins = "gpio14";
		function = PMIC_GPIO_FUNC_NORMAL;
		drive-push-pull;
		input-enable;
		bias-high-impedance;
		qcom,drive-strength = <PMIC_GPIO_STRENGTH_LOW>;
		power-source = <PM8994_GPIO_VPH>;
	};

	pm8994_pm_divclk1: pm_divclk1_gpio {
		pins = "gpio15";
		function = "func1";
		output-low;
		drive-push-pull;
		bias-high-impedance;
		qcom,drive-strength = <PMIC_GPIO_STRENGTH_LOW>;
		power-source = <PM8994_GPIO_VPH>;
	};

	pm8994_pmi_clk: pmi_clk_gpio {
		pins = "gpio16";
		function = PMIC_GPIO_FUNC_NORMAL;
		drive-push-pull;
	};

	pm8994_gpio_17: pm_gpio17_nc {
		pins = "gpio17";
		function = PMIC_GPIO_FUNC_NORMAL;
		drive-push-pull;
		bias-high-impedance;
		power-source = <PM8994_GPIO_VPH>;
	};

	pm8994_rome_sleep: rome_sleep {
		pins = "gpio18";
		function = PMIC_GPIO_FUNC_FUNC2;
		output-low;
		drive-push-pull;
		bias-disable;
		qcom,drive-strength = <PMIC_GPIO_STRENGTH_MED>;
		power-source = <PM8994_GPIO_S4>;
	};

	pm8994_gpio_19: pm_gpio19_nc {
		pins = "gpio19";
		function = PMIC_GPIO_FUNC_NORMAL;
		output-low;
		drive-push-pull;
		bias-high-impedance;
		qcom,drive-strength = <PMIC_GPIO_STRENGTH_NO>;
		power-source = <PM8994_GPIO_VPH>;
	};

	pm8994_gpio_22: pm_gpio22_nc {
		pins = "gpio17";
		function = PMIC_GPIO_FUNC_NORMAL;
		drive-push-pull;
		bias-high-impedance;
		power-source = <PM8994_GPIO_VPH>;
	};
};

&pm8994_mpps {
	pinctrl-names = "default";
	pinctrl-0 = <&pm8994_mpp_lcd_id_adc &pm8994_mpp4
			&pm8994_mpp_flash_th &pm8994_mpp6_def
			&pm8994_mpp_rf_id>;

	gpio-line-names =
		"SDC_UIM_VBIAS",
		"LCD_ID_ADC",
		"VREF_DACX",
		"NC",
		"FLASH_THERM",
		"NC",
		"NC",
		"RF_ID";

	pm8994_mpp_lcd_id_adc: lcd_id_adc_mpp {
		pins = "mpp2";
		function = PMIC_MPP_FUNC_ANALOG;
		input-enable;
		qcom,amux-route = <PMIC_MPP_AMUX_ROUTE_CH6>;
	};

	pm8994_mpp4: pm_mpp4_nc {
		pins = "mpp4";
		function = PMIC_MPP_FUNC_DIGITAL;
		bias-high-impedance;
		power-source = <PM8994_GPIO_VPH>;
	};

	pm8994_mpp_flash_th: flash_therm_mpp {
		pins = "mpp5";
		function = PMIC_MPP_FUNC_ANALOG;
		input-enable;
		qcom,amux-route = <PMIC_MPP_AMUX_ROUTE_CH5>;
	};

	pm8994_mpp6_def: mpp6_nc {
		pins = "mpp6";
		function = PMIC_MPP_FUNC_DIGITAL;
		bias-high-impedance;
	};

	pm8994_mpp_rf_id: rf_id_mpp {
		pins = "mpp8";
		function = PMIC_MPP_FUNC_ANALOG;
		input-enable;
		qcom,amux-route = <PMIC_MPP_AMUX_ROUTE_CH8>;
	};
};

&pmi8994_gpios {
	pinctrl-names = "default";
	pinctrl-0 = <&pmi8994_vib_ldo_en &pmi8994_gpio_2 &pmi8994_gpio_3
		     &pmi8994_gpio_4 &pmi8994_gpio_5 &pmi8994_gpio_6
		     &pmi8994_gpio_7 &pmi8994_gpio_8 &pmi8994_usb_switch_sel
		     &pmi8994_gpio_10>;

	gpio-line-names =
		"VIB_LDO_EN",
		"NC",
		"NC",
		"NC",
		"NC",
		"NC",
		"NC",
		"NC",
		"USB_SWITCH_SEL",
		"NC";

	pmi8994_vib_ldo_en: vib_ldo_en_gpio {
		pins = "gpio1";
		function = PMIC_GPIO_FUNC_NORMAL;
		drive-push-pull;
		output-low;
		bias-disable;
		power-source = <PM8994_GPIO_S4>;
	};

	pmi8994_gpio_2: pmi_gpio2_nc {
		pins = "gpio2";
		function = PMIC_GPIO_FUNC_NORMAL;
		drive-push-pull;
		input-enable;
		bias-high-impedance;
		qcom,drive-strength = <PMIC_GPIO_STRENGTH_NO>;
		power-source = <PM8994_GPIO_VPH>;
	};

	pmi8994_gpio_3: pmi_gpio3_nc {
		pins = "gpio3";
		function = PMIC_GPIO_FUNC_NORMAL;
		drive-push-pull;
		input-enable;
		bias-high-impedance;
		qcom,drive-strength = <PMIC_GPIO_STRENGTH_NO>;
		power-source = <PM8994_GPIO_VPH>;
	};

	pmi8994_gpio_4: pmi_gpio4_nc {
		pins = "gpio4";
		function = PMIC_GPIO_FUNC_NORMAL;
		drive-push-pull;
		output-high;
		qcom,drive-strength = <PMIC_GPIO_STRENGTH_LOW>;
		power-source = <PM8994_GPIO_S4>;
	};

	pmi8994_gpio_5: pmi_gpio5_nc {
		pins = "gpio5";
		function = PMIC_GPIO_FUNC_NORMAL;
		drive-push-pull;
		output-high;
		qcom,drive-strength = <PMIC_GPIO_STRENGTH_NO>;
		power-source = <PM8994_GPIO_S4>;
	};

	pmi8994_gpio_6: pmi_gpio6_nc {
		pins = "gpio6";
		function = PMIC_GPIO_FUNC_NORMAL;
		drive-push-pull;
		output-high;
		qcom,drive-strength = <PMIC_GPIO_STRENGTH_LOW>;
		power-source = <PM8994_GPIO_S4>;
	};

	pmi8994_gpio_7: pmi_gpio7_nc {
		pins = "gpio7";
		function = PMIC_GPIO_FUNC_NORMAL;
		drive-push-pull;
		output-high;
		qcom,drive-strength = <PMIC_GPIO_STRENGTH_LOW>;
		power-source = <PM8994_GPIO_S4>;
	};

	pmi8994_gpio_8: pmi_gpio8_nc {
		pins = "gpio8";
		function = PMIC_GPIO_FUNC_NORMAL;
		drive-push-pull;
		output-high;
		qcom,drive-strength = <PMIC_GPIO_STRENGTH_LOW>;
		power-source = <PM8994_GPIO_S4>;
	};

	pmi8994_usb_switch_sel: usb_switch_sel {
		pins = "gpio9";
		function = PMIC_GPIO_FUNC_NORMAL;
		drive-push-pull;
	};

	pmi8994_gpio_10: pmi_gpio10_nc {
		pins = "gpio10";
		function = PMIC_GPIO_FUNC_NORMAL;
		output-low;
		drive-push-pull;
		bias-disable;
		qcom,drive-strength = <PMIC_GPIO_STRENGTH_NO>;
		power-source = <PM8994_GPIO_S4>;
	};
};

&pmi8994_mpps {
	pinctrl-names = "default";
	pinctrl-0 = <&pmi8994_mpp_usbid_dis &pmi8994_mpp_flash_led_now
			&pmi8994_mpp4_nc>;

	gpio-line-names =
		"USB_ID_DISCHG",
		"FLASH_LED_NOW",
		"PMI_SPON",
		"NC",
		"NC";

	pmi8994_mpp_usbid_dis: usb_id_dischg_mpp {
		pins = "mpp1";
		function = PMIC_MPP_FUNC_DIGITAL;
		input-enable;
		power-source = <PM8994_GPIO_S4>;
	};

	pmi8994_mpp_flash_led_now: flash_led_now_mpp {
		pins = "mpp2";
		function = PMIC_MPP_FUNC_DIGITAL;
		input-enable;
		power-source = <PM8994_GPIO_S4>;
	};

	pmi8994_mpp4_nc: pmi_mpp4_nc {
		pins = "mpp4";
		function = PMIC_MPP_FUNC_DIGITAL;
		bias-high-impedance;
		power-source = <PM8994_MPP_VPH>;
	};
};

